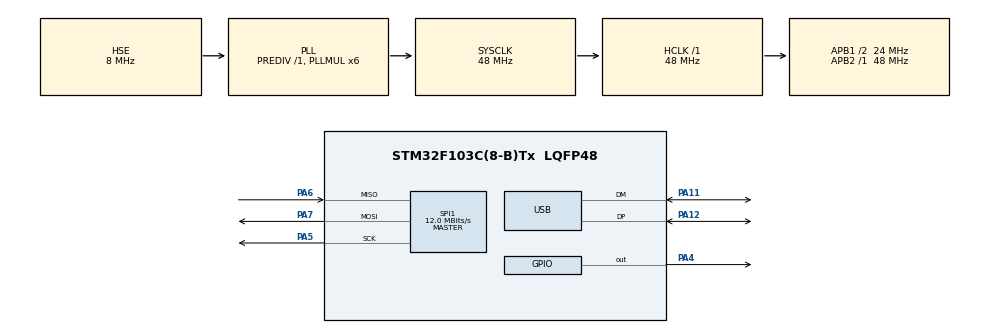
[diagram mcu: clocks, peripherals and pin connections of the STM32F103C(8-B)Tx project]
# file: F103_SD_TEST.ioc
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Mcu.Family=STM32F1
Mcu.Name=STM32F103C(8-B)Tx
Mcu.Package=LQFP48
NVIC.PriorityGroup=NVIC_PRIORITYGROUP_4
NVIC.USB_LP_CAN1_RX0_IRQn=true\:0\:0\:false\:false\:true\:false\:true\:true
PA11.Mode=Device
PA11.Signal=USB_DM
PA12.Mode=Device
PA12.Signal=USB_DP
PA13.Mode=Serial_Wire
PA13.Signal=SYS_JTMS-SWDIO
PA14.Mode=Serial_Wire
PA14.Signal=SYS_JTCK-SWCLK
PA4.GPIO_Speed=GPIO_SPEED_FREQ_HIGH
PA4.Signal=GPIO_Output
PA5.Mode=Full_Duplex_Master
PA5.Signal=SPI1_SCK
PA6.Mode=Full_Duplex_Master
PA6.Signal=SPI1_MISO
PA7.Mode=Full_Duplex_Master
PA7.Signal=SPI1_MOSI
PC14-OSC32_IN.Mode=LSE-External-Oscillator
PC14-OSC32_IN.Signal=RCC_OSC32_IN
PC15-OSC32_OUT.Mode=LSE-External-Oscillator
PC15-OSC32_OUT.Signal=RCC_OSC32_OUT
PD0-OSC_IN.Mode=HSE-External-Oscillator
PD0-OSC_IN.Signal=RCC_OSC_IN
PD1-OSC_OUT.Mode=HSE-External-Oscillator
PD1-OSC_OUT.Signal=RCC_OSC_OUT
ProjectManager.HeapSize=0x200
ProjectManager.StackSize=0x1400
ProjectManager.TargetToolchain=MDK-ARM V5.32
RCC.AHBFreq_Value=48000000
RCC.APB1CLKDivider=RCC_HCLK_DIV2
RCC.APB1Freq_Value=24000000
RCC.APB1TimFreq_Value=48000000
RCC.APB2Freq_Value=48000000
RCC.APB2TimFreq_Value=48000000
RCC.HCLKFreq_Value=48000000
RCC.PLLMUL=RCC_PLL_MUL6
RCC.PLLSourceVirtual=RCC_PLLSOURCE_HSE
RCC.SYSCLKFreq_VALUE=48000000
RCC.SYSCLKSource=RCC_SYSCLKSOURCE_PLLCLK
RCC.USBFreq_Value=48000000
SPI1.BaudRatePrescaler=SPI_BAUDRATEPRESCALER_4
SPI1.CLKPhase=SPI_PHASE_2EDGE
SPI1.CLKPolarity=SPI_POLARITY_HIGH
SPI1.CalculateBaudRate=12.0 MBits/s
SPI1.Direction=SPI_DIRECTION_2LINES
SPI1.Mode=SPI_MODE_MASTER
SPI1.VirtualType=VM_MASTER
USB_DEVICE.CLASS_NAME_FS=MSC
USB_DEVICE.VirtualMode=Msc
USB_DEVICE.VirtualModeFS=Msc_FS
VP_USB_DEVICE_VS_USB_DEVICE_MSC_FS.Mode=MSC_FS
board=custom

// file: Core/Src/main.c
/* USER CODE BEGIN Header */
/**
  ******************************************************************************
  * @file           : main.c
  * @brief          : Main program body
  ******************************************************************************
  * @attention
  *
  * Copyright (c) 2023 STMicroelectronics.
  * All rights reserved.
  *
  * This software is licensed under terms that can be found in the LICENSE file
  * in the root directory of this software component.
  * If no LICENSE file comes with this software, it is provided AS-IS.
  *
  ******************************************************************************
  */
/* USER CODE END Header */
#include "main.h"
#include "spi.h"
#include "usb_device.h"
#include "gpio.h"

/* USER CODE BEGIN Includes */
#include "SDdriver.h"
#include "stdio.h"
#include "./FatFS/ff.h"
#include "./FatFS/ff_gen_drv.h"
#include "./FatFS/drivers/sd_diskio.h"
/* USER CODE END Includes */

void SystemClock_Config(void);

/* USER CODE BEGIN 0 */
/**
  ******************************************************************************
  *                              定义变量
  ******************************************************************************
  */
char SDPath[4];                   /* SD卡逻辑设备路径 */
FATFS fs;													/* FatFs文件系统对象 */
FIL file;													/* 文件对象 */
FRESULT f_res;                    /* 文件操作结果 */
UINT fnum;            					  /* 文件成功读写数量 */
BYTE ReadBuffer[1024]={0};        /* 读缓冲区 */
BYTE WriteBuffer[]= "欢迎使用野火STM32开发板 今天是个好日子，新建文件系统测试文件\r\n";
/* USER CODE END 0 */

int main(void)
{
  /* USER CODE BEGIN 1 */
	//SD_Error Status = SD_RESPONSE_NO_ERROR;
  /* USER CODE END 1 */

  /* MCU Configuration--------------------------------------------------------*/

  /* Reset of all peripherals, Initializes the Flash interface and the Systick. */
  HAL_Init();

  /* Configure the system clock */
  SystemClock_Config();

  /* Initialize all configured peripherals */
  MX_GPIO_Init();
  MX_USB_DEVICE_Init();
  MX_SPI1_Init();
  /* USER CODE BEGIN 2 */
	//SD_Init();
  /* USER CODE END 2 */

  /* Infinite loop */
  /* USER CODE BEGIN WHILE */
  while (1)
  {
		//SD_CardInfo count;
		//SD_GetCardInfo(&count);
		//uint8_t buf[10];
		//sprintf((char *)buf,"%d\r\n",count.CardBlockSize);
		//CDC_Transmit_FS(buf,10);
		HAL_Delay(1000);
    /* USER CODE END WHILE */

  }
}

void SystemClock_Config(void)
{
  RCC_OscInitTypeDef RCC_OscInitStruct = {0};
  RCC_ClkInitTypeDef RCC_ClkInitStruct = {0};
  RCC_PeriphCLKInitTypeDef PeriphClkInit = {0};

  /** Initializes the RCC Oscillators according to the specified parameters
  * in the RCC_OscInitTypeDef structure.
  */
  RCC_OscInitStruct.OscillatorType = RCC_OSCILLATORTYPE_HSE;
  RCC_OscInitStruct.HSEState = RCC_HSE_ON;
  RCC_OscInitStruct.HSEPredivValue = RCC_HSE_PREDIV_DIV1;
  RCC_OscInitStruct.HSIState = RCC_HSI_ON;
  RCC_OscInitStruct.PLL.PLLState = RCC_PLL_ON;
  RCC_OscInitStruct.PLL.PLLSource = RCC_PLLSOURCE_HSE;
  RCC_OscInitStruct.PLL.PLLMUL = RCC_PLL_MUL6;
  if (HAL_RCC_OscConfig(&RCC_OscInitStruct) != HAL_OK)
  {
    Error_Handler();
  }

  /** Initializes the CPU, AHB and APB buses clocks
  */
  RCC_ClkInitStruct.ClockType = RCC_CLOCKTYPE_HCLK|RCC_CLOCKTYPE_SYSCLK
                              |RCC_CLOCKTYPE_PCLK1|RCC_CLOCKTYPE_PCLK2;
  RCC_ClkInitStruct.SYSCLKSource = RCC_SYSCLKSOURCE_PLLCLK;
  RCC_ClkInitStruct.AHBCLKDivider = RCC_SYSCLK_DIV1;
  RCC_ClkInitStruct.APB1CLKDivider = RCC_HCLK_DIV2;
  RCC_ClkInitStruct.APB2CLKDivider = RCC_HCLK_DIV1;

  if (HAL_RCC_ClockConfig(&RCC_ClkInitStruct, FLASH_LATENCY_1) != HAL_OK)
  {
    Error_Handler();
  }
  PeriphClkInit.PeriphClockSelection = RCC_PERIPHCLK_USB;
  PeriphClkInit.UsbClockSelection = RCC_USBCLKSOURCE_PLL;
  if (HAL_RCCEx_PeriphCLKConfig(&PeriphClkInit) != HAL_OK)
  {
    Error_Handler();
  }
}

void Error_Handler(void)
{
  __disable_irq();
  while (1)
  {
  }
}
